# AE402FA0E5597LE0_CM55_HP_View register map
Vendor: Alif Semiconductor; Series: E4; File version: 1.0
CPU: CM55 r1p0, selectable endian, MPU, FPU, double-precision FPU, DSP, VTOR, 8 interrupt priority bits, 1 SAU regions
Registers are 32-bit, read-write, reset 0x0 unless marked. A register's access mark holds for its fields unless they carry their own. Offsets are from the block's base; [hi:lo] are bit positions; lines under a group give offsets from that group; {n}, {i} and the like mark numbered series.

## REFCLK_CNTControl
Base 0x1A200000
Same registers: S32K_CNTControl 0x1A400000
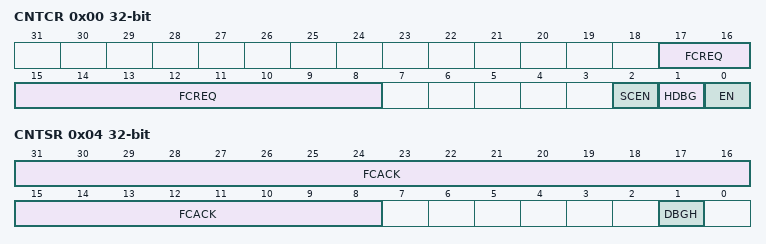
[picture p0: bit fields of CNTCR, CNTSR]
0x00 CNTCR (reset mask 0xFFFFFFF9) — Counter Control Register
  [17:8] FCREQ — Frequency change request. Specifies the index of the CNTFIDn register that holds the counter new frequency. Changing the value of this field requests a change to the counter update frequency. Any non-required most-significant bits are read-only and reserved.
  [2] SCEN — Scale Enable. This bit can only be changed when the counter is disabled (when CNTCR[EN] = 0x0). If the value of CNTCR[SCEN] changes when CNTCR[EN] = 0x1 then the counter value becomes unknown and remains unknown on future ticks of the clock.
    0=Scaling disabled. The counter value is incremented by 0x1 for each counter tick.; 1=Scaling enabled. The counter value is incremented by CNTSCR[SCALEVAL] for each counter tick.
  [1] HDBG — Halt-on-debug. Controls whether a halt-on-debug request halts the system counter.
    0=The counter ignores the halt-on-debug request; 1=When the halt-on-debug request is activated the counter halts
  [0] EN — Counter enable.
    0=System counter disabled; 1=System counter enabled
0x04 CNTSR ro (reset mask 0xFFFFFFFD) — Counter Status Register
  [31:8] FCACK — Frequency change acknowledge. Specifies the index of the CNTFIDn register that holds the counter new frequency.
  [1] DBGH — Indicates whether the counter is halted because of a halt-on-debug request.
    0=Counter is not halted; 1=Counter is halted
0x08 CNTCVL reset not defined — Counter Count Value Low Register
  [31:0] COUNTVALUE_LO — Bits [31:0] of the current counter value.
0x0C CNTCVH reset not defined — Counter Count Value High Register
  [31:0] COUNTVALUE_HI — Bits [63:32] of the current counter value.

## REFCLK_CNTRead
Base 0x1A210000
Same registers: S32K_CNTRead 0x1A410000
0x00 CNTCVL ro reset not defined — Read-only Version of CNTCVL Register
  [31:0] COUNTVALUE_LO — Read-only version of CNTCVL register.
0x04 CNTCVH ro reset not defined — Read-only Version of CNTCVH Register
  [31:0] COUNTVALUE_HI — Read-only version of CNTCVH register

## PINMUX
Base 0x1A603000
{0x0+0x20*i} PINMUX_CFG[{i}] (i=0..17) group
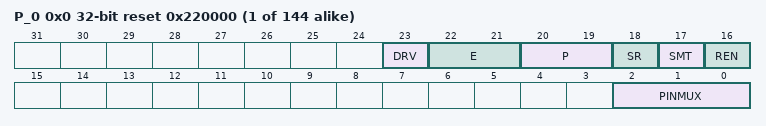
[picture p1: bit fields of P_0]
  {0x0+4j} P_{j} reset 0x220000 (j=0..7) — Control Register for Port n, Pin {j}
    [23] DRV — Driver type
      0=Push-pull; 1=Open drain
    [22:21] E — Output drive strength NOTE: Reset value is 0x3 (12 mA) for registers P4_4, P4_5, P4_6, P4_7
      0=2 mA; 1=4 mA; 2=8 mA; 3=12 mA
    [20:19] P — Driver disabled state control
      0=High-Z; 1=Pull-up; 2=Pull-down; 3=Bus keeper
    [18] SR — Slew rate
      0=Slow; 1=Fast
    [17] SMT — Schmitt trigger (hysteresis) enable
      0=No hysteresis; 1=Hysteresis enabled
    [16] REN — Receiver enable NOTE: Reset value is 0x1 for registers P4_4, P4_5, P4_6, P4_7
      0=Receiver disabled, pin reads return 0; 1=Receiver enabled
    [2:0] PINMUX — Pin multiplexing control field 0x1-0xN: Selects other peripherals as shown in table Pin Function Multiplexing of the device series-specific Datasheet. Un-mapped: Select GPIOn_{j} NOTE: Reset value is 0x1 for registers P4_4, P4_5, P4_6, P4_7
      0=Selects GPIOn_{j} signal from GPIOn peripheral

## STOP_MODE
Base 0x1A60F000
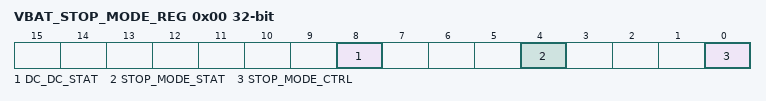
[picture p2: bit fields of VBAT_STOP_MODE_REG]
0x00 VBAT_STOP_MODE_REG — VBAT Stop Mode Control and Status Register
  [8] DC_DC_STAT ro — DC-DC Status Reflects the real-time status of DC-DC power
    0=DC-DC is ON; 1=DC-DC is OFF
  [4] STOP_MODE_STAT write-1-clears — Stop Mode Status - HW sets this bit when DC-DC was turned off - SW clears this bit by writing 0x1
  [0] STOP_MODE_CTRL — Stop Mode Control - SW sets this bit to enter stop mode - HW clears this bit when there is a wake-up event
